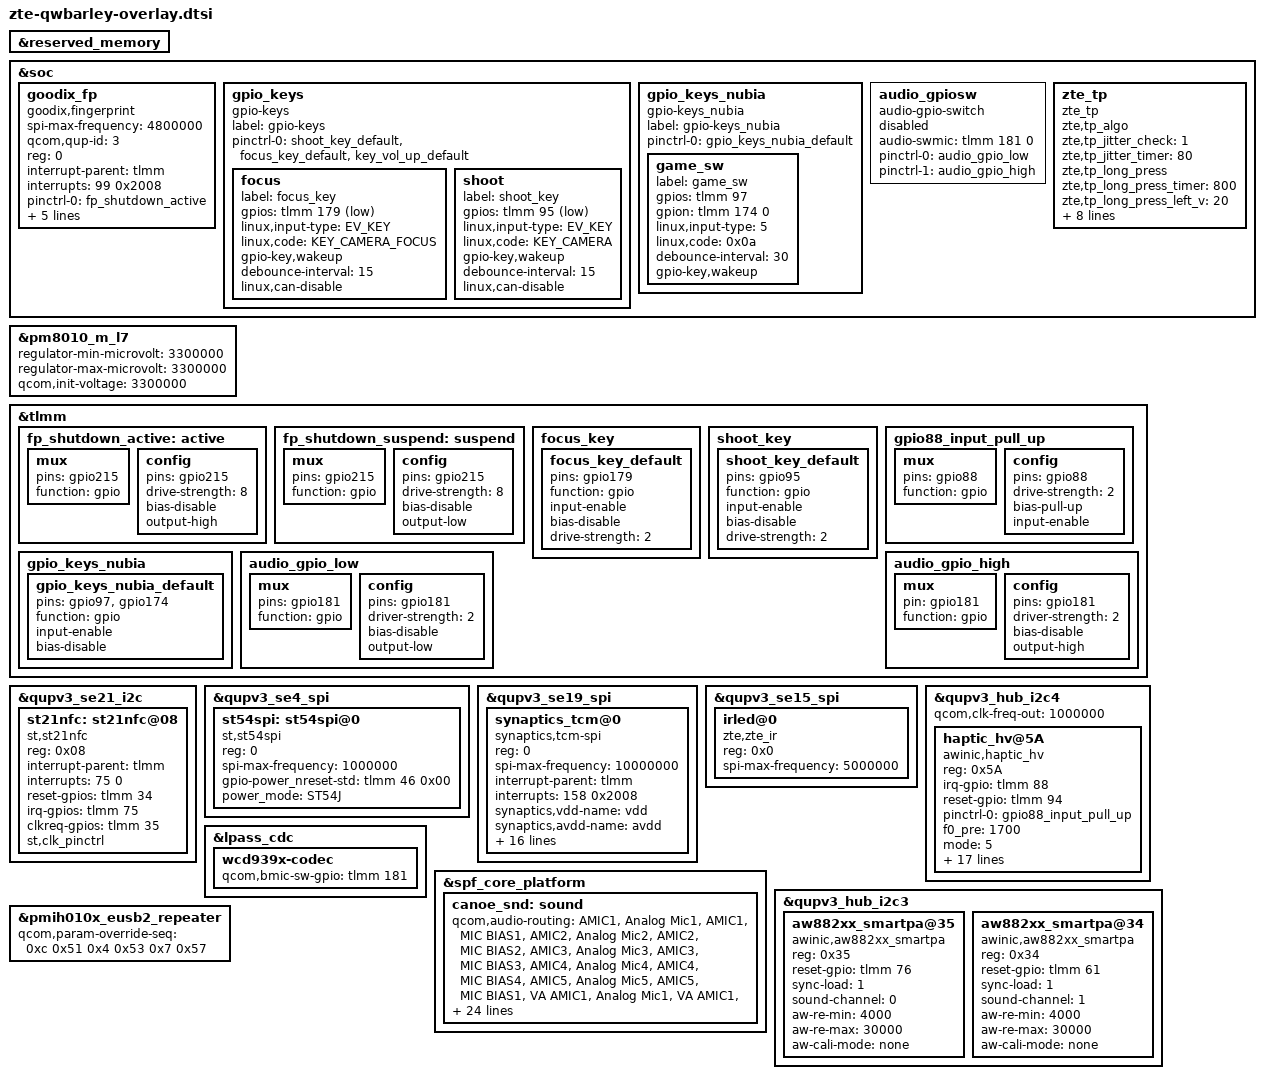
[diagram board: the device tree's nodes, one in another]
/* dtsi for aston board (PQ85A01)*/
#include <dt-bindings/gpio/gpio.h>
#include <dt-bindings/input/input.h>
#include <dt-bindings/clock/qcom,rpmh.h>


&reserved_memory {
};

&soc {
	goodix_fp {
		status = "ok";
		compatible = "goodix,fingerprint";
		spi-max-frequency = <4800000>;
		qcom,qup-id = <3>;
		reg = <0>;

		interrupt-parent = <&tlmm>;
		interrupts = <99 0x2008>;
		pinctrl-names = "goodix_active", "goodix_suspend";
		pinctrl-0 = <&fp_shutdown_active>;
		pinctrl-1 = <&fp_shutdown_suspend>;

		fp-gpio-reset = <&tlmm 215 0x0>;
		fp-gpio-irq = <&tlmm 99 0x2008>;
		vdd-supply = <&L7M>;
		interrupt-names = "goodix_wake_up";

		panel = <&dsi_bf375_rm692h5_6p8_dev0_dsc_cmd>;
	};

	gpio_keys {
		compatible = "gpio-keys";
		label = "gpio-keys";
		pinctrl-names = "default";
		pinctrl-0 = <&shoot_key_default &focus_key_default &key_vol_up_default>;

		focus {
			label = "focus_key";
			gpios = <&tlmm 179 GPIO_ACTIVE_LOW>;
			linux,input-type = <EV_KEY>;
			linux,code = <KEY_CAMERA_FOCUS>;   //0x210 528
			gpio-key,wakeup;
			debounce-interval = <15>;
			linux,can-disable;
		};

		shoot {
			label = "shoot_key";
			gpios = <&tlmm 95 GPIO_ACTIVE_LOW>;
			linux,input-type = <EV_KEY>; //0x01
			linux,code = <KEY_CAMERA>;  //212
			gpio-key,wakeup;
			debounce-interval = <15>;
			linux,can-disable;
		};
	};

	gpio_keys_nubia {
		status = "ok";
		compatible = "gpio-keys_nubia";
		label = "gpio-keys_nubia";
		pinctrl-names ="default";
		pinctrl-0 = <&gpio_keys_nubia_default>;
		game_sw {
			label = "game_sw";
			gpios = <&tlmm 97 0>;
			gpion = <&tlmm 174 0>;
			linux,input-type = <5>;
			linux,code = <0x0a>;
			debounce-interval = <30>;
			gpio-key,wakeup;
		};
	};

        audio_gpiosw {
		status = "disabled";
		compatible = "audio-gpio-switch";
		audio-swmic = <&tlmm 181 0>;
		pinctrl-names = "audio_sys_off", "audio_sys_on";
		pinctrl-0 = <&audio_gpio_low>;
		pinctrl-1 = <&audio_gpio_high>;
	};

	zte_tp:zte_tp {
		compatible = "zte_tp";
		zte,tp_algo;
		zte,tp_jitter_check = <1>;
		zte,tp_jitter_timer = <80>;
		zte,tp_long_press;
		zte,tp_long_press_timer = <800>;
		zte,tp_long_press_left_v = <20>;
		zte,tp_long_press_right_v = <20>;
		zte,tp_long_press_left_h = <20>; /*camera */
		zte,tp_long_press_right_h = <20>; /*charger */
		zte,tp_edge_click_suppression_pixel = <20>;
		zte,ufp_enable;
		zte,ufp_circle_center_x = <6080>;
		zte,ufp_circle_center_y = <20240>;
		zte,ufp_circle_radius = <1200>;
	};
};

&pm8010_m_l7 {
        regulator-min-microvolt = <3300000>;
        regulator-max-microvolt = <3300000>;
        qcom,init-voltage = <3300000>;
};

&tlmm {
	fp_shutdown_active:active{
		mux{
			pins = "gpio215";
			function = "gpio";
		};
		config{
			pins = "gpio215";
			drive-strength = <8>;
			bias-disable;
			output-high;
		};
	};

	fp_shutdown_suspend:suspend{
		mux{
			pins = "gpio215";
			function = "gpio";
		};
		config{
			pins = "gpio215";
			drive-strength = <8>;
			bias-disable;
			output-low;
		};
	};

	focus_key {
		focus_key_default: focus_key_default {
			pins = "gpio179";
			function = "gpio";
			input-enable;
			bias-disable;
			drive-strength = <2>;   /* 2 mA */
		};
	};
	shoot_key {
		shoot_key_default: shoot_key_default {
			pins = "gpio95";
			function = "gpio";
			input-enable;
			bias-disable;
			drive-strength = <2>;   /* 2 mA */
		};
	};

	gpio88_input_pull_up: gpio88_input_pull_up {
		mux {
			 pins = "gpio88";
			 function = "gpio";
		};

		config {
			pins = "gpio88";
			drive-strength = <2>;
			bias-pull-up;
			input-enable;
		};
	};

	gpio_keys_nubia {
		gpio_keys_nubia_default: gpio_keys_nubia_default {
			pins = "gpio97", "gpio174";
			function = "gpio";
			input-enable;
			bias-disable;
		};
	};

	audio_gpio_low:audio_gpio_low {
		mux {
			pins = "gpio181";
			function = "gpio";
		};

		config {
			pins = "gpio181";
			driver-strength = <2>;
			bias-disable;
			output-low;
		};
	};

	audio_gpio_high:audio_gpio_high {
		mux {
			pin = "gpio181";
			function = "gpio";
		};

		config {
			pins = "gpio181";
			driver-strength = <2>;
			bias-disable;
			output-high;
		};
	};
};

/* add zte nfc ir brgin */
&qupv3_se21_i2c {
	status = "ok";
	/delete-node/ nq@28;
	st21nfc: st21nfc@08 {
		compatible = "st,st21nfc";
		reg = <0x08>;
		interrupt-parent = <&tlmm>;
		interrupts = <75  0>;
		reset-gpios = <&tlmm 34 0x00>;
		irq-gpios = <&tlmm 75 0x00>;
		//boost-gpios = <&tlmm 90 0x00>;
		//pidle-gpios = <&tlmm 48 0x00>;
		clkreq-gpios = <&tlmm 35 0x00>;
		//clocks = <&clock_rpmh RPMH_RF_CLK3>;
		//clock-names = "nfc_ref_clk";
		st,clk_pinctrl;
		status = "ok";
	};
};

&qupv3_se4_spi {
	status = "ok";
	st54spi: st54spi@0 {
		compatible = "st,st54spi";
		reg = <0>;
		spi-max-frequency = <1000000>;
		/* gpio used as SE_PWR_REQ or SE_nRESET */
		gpio-power_nreset-std = <&tlmm 46 0x00>;

		/* Power management mode: none, ST54H (default), ST54J */
		power_mode = "ST54J";
		status = "ok";
	};
};

&qupv3_se19_spi {

	status = "ok";

	synaptics_tcm@0 {
		compatible = "synaptics,tcm-spi";
		reg = <0>;
		spi-max-frequency = <10000000>;
		interrupt-parent = <&tlmm>;
		interrupts = <158 0x2008>;
		synaptics,vdd-name = "vdd";
		synaptics,avdd-name = "avdd";
		vdd-supply = <&L4B>;
		avdd-supply = <&L14B>;
		synaptics,power-delay-ms = <200>;
		synaptics,irq-gpio = <&tlmm 158 0x2008>;
		synaptics,irq-on-state = <0>;
		synaptics,reset-gpio = <&tlmm 66 0x0000>;
		synaptics,reset-on-state = <0>;
		synaptics,reset-active-ms = <20>;
		synaptics,reset-delay-ms = <200>;
		synaptics,spi-mode = <0>;
		synaptics,spi-byte-delay-us = <0>;
		synaptics,spi-block-delay-us = <0>;

		pinctrl-names = "ts_active", "ts_suspend";
		pinctrl-0 = <&ts_active>;
		pinctrl-1 = <&ts_int_suspend &ts_reset_suspend>;
		pinctrl-2 = <&ts_release>;

		panel = <&dsi_bf375_rm692h5_6p8_dev0_dsc_cmd>;
	};
};

&qupv3_se15_spi {
	status = "ok";
	irled@0 {
		status = "ok";
		compatible = "zte,zte_ir";
		reg = <0x0>;
		spi-max-frequency = <5000000>;
	};
};
/* add zte nfc ir end */

/* add zte haptic  */
&qupv3_hub_i2c4  {
	status = "ok";
	qcom,clk-freq-out = <1000000>;
	haptic_hv@5A {
		compatible = "awinic,haptic_hv";
		reg = <0x5A>;
		irq-gpio = <&tlmm 88 0>;
		reset-gpio = <&tlmm 94 0>;
		pinctrl-names = "irq_active";
		pinctrl-0 = <&gpio88_input_pull_up>;
		f0_pre = < 1700 >;
		mode = /bits/ 8 < 5 >;

		aw8693x_f0_cali_percent = /bits/ 8 < 15 >;
		aw8693x_gain_bypass = /bits/ 8 < 1 >;
		aw8693x_uvlo_vol_default = /bits/ 8 < 0 >;
		aw8693x_cont_smart_loop = /bits/ 8 < 0 >;
		aw8693x_cont_drv1_lvl = /bits/ 8 < 0x7F >;
		aw8693x_cont_lra_vrms = < 1000 >;
		aw8693x_cont_drv1_time = /bits/ 8 < 0x04 >;
		aw8693x_cont_drv2_time = /bits/ 8 < 0x14 >;
		aw8693x_cont_track_margin = /bits/ 8 < 0x0F >;
		aw8693x_cont_brk_gain = /bits/ 8 < 0x08 >;
		aw8693x_cont_brk_time = /bits/ 8 < 0x08 >;
		aw8693x_duration_time = /bits/ 8 < 20 30 60 >;
		aw8693x_d2s_gain = /bits/ 8 < 0x04 >;
		aw8693x_trig_config = /bits/ 8 < 0 0 0 1 0 2 0 0
						 0 0 0 1 0 2 0 0
						 0 0 0 1 0 2 0 0 >;
		aw8693x_bst_vol_default = /bits/ 8 < 0x0f >;
		aw8693x_is_enabled_track_en;
		/* aw8693x_is_enabled_auto_bst; */
		/* aw8693x_is_enabled_one_wire; */
	};
};

&lpass_cdc {
	wcd939x-codec {
		qcom,bmic-sw-gpio = <&tlmm 181 0>;
	};
};

&spf_core_platform  {
	canoe_snd: sound {
		qcom,audio-routing =
			"AMIC1", "Analog Mic1",
			"AMIC1", "MIC BIAS1",
			"AMIC2", "Analog Mic2",
			"AMIC2", "MIC BIAS2",
			"AMIC3", "Analog Mic3",
			"AMIC3", "MIC BIAS3",
			"AMIC4", "Analog Mic4",
			"AMIC4", "MIC BIAS4",
			"AMIC5", "Analog Mic5",
			"AMIC5", "MIC BIAS1",
			"VA AMIC1", "Analog Mic1",
			"VA AMIC1", "VA MIC BIAS1",
			"VA AMIC2", "Analog Mic2",
			"VA AMIC2", "VA MIC BIAS2",
			"VA AMIC3", "Analog Mic3",
			"VA AMIC3", "VA MIC BIAS3",
			"VA AMIC4", "Analog Mic4",
			"VA AMIC4", "VA MIC BIAS4",
			"VA AMIC5", "Analog Mic5",
			"VA AMIC5", "VA MIC BIAS1",
			"TX DMIC0", "Digital Mic0",
			"TX DMIC0", "MIC BIAS1",
			"TX DMIC1", "Digital Mic1",
			"TX DMIC1", "MIC BIAS1",
			"TX DMIC2", "Digital Mic2",
			"TX DMIC2", "MIC BIAS3",
			"TX DMIC3", "Digital Mic3",
			"TX DMIC3", "MIC BIAS3",
			"IN1_HPHL", "HPHL_OUT",
			"IN2_HPHR", "HPHR_OUT",
			"IN3_EAR", "AUX_OUT",
			"RX_TX DEC0_INP", "TX DEC0 MUX",
			"RX_TX DEC1_INP", "TX DEC1 MUX",
			"RX_TX DEC2_INP", "TX DEC2 MUX",
			"RX_TX DEC3_INP", "TX DEC3 MUX",
			"TX SWR_INPUT", "WCD_TX_OUTPUT",
			"VA SWR_INPUT", "VA_SWR_CLK",
			"VA SWR_INPUT", "WCD_TX_OUTPUT",
			"VA_AIF1 CAP", "VA_SWR_CLK",
			"VA_AIF2 CAP", "VA_SWR_CLK",
			"VA_AIF3 CAP", "VA_SWR_CLK",
			"VA DMIC0", "Digital Mic0",
			"VA DMIC1", "Digital Mic1",
			"VA DMIC2", "Digital Mic2",
			"VA DMIC3", "Digital Mic3",
			"VA DMIC0", "VA MIC BIAS1",
			"VA DMIC1", "VA MIC BIAS1",
			"VA DMIC2", "VA MIC BIAS3",
			"VA DMIC3", "VA MIC BIAS3";
	};
};

/* AWINIC AW882XX Smart PA */
&qupv3_hub_i2c3 {
	status = "okay";
	aw882xx_smartpa@35 {
		compatible = "awinic,aw882xx_smartpa";
		reg = <0x35>;
		reset-gpio = <&tlmm 76 0>;
		sync-load = <1>;
		sound-channel = <0>;
		aw-re-min = <4000>;
		aw-re-max= <30000>;
		aw-cali-mode = "none";
	};
	aw882xx_smartpa@34 {
		compatible = "awinic,aw882xx_smartpa";
		reg = <0x34>;
		reset-gpio = <&tlmm 61 0>;
		/* irq-gpio = <&tlmm xx 0x2008> */
		sync-load = <1>;
		sound-channel = <1>; /* 0: pri_l, 1:pri_r, 2:sec_l, 3:sec_r */
		aw-re-min = <4000>;
		aw-re-max= <30000>;
		aw-cali-mode = "none";
	};
};
/* AWINIC AW882XX Smart PA End */

&pmih010x_eusb2_repeater {
	qcom,param-override-seq =
		/* <value reg_offset> */
		/* Adjust HS trasmit amplitude */
		<0xc 0x51
		/* Disconnect Threshold */
		 0x4 0x53
		/* Tx pre-emphasis tuning */
		 0x7 0x57>;
};
